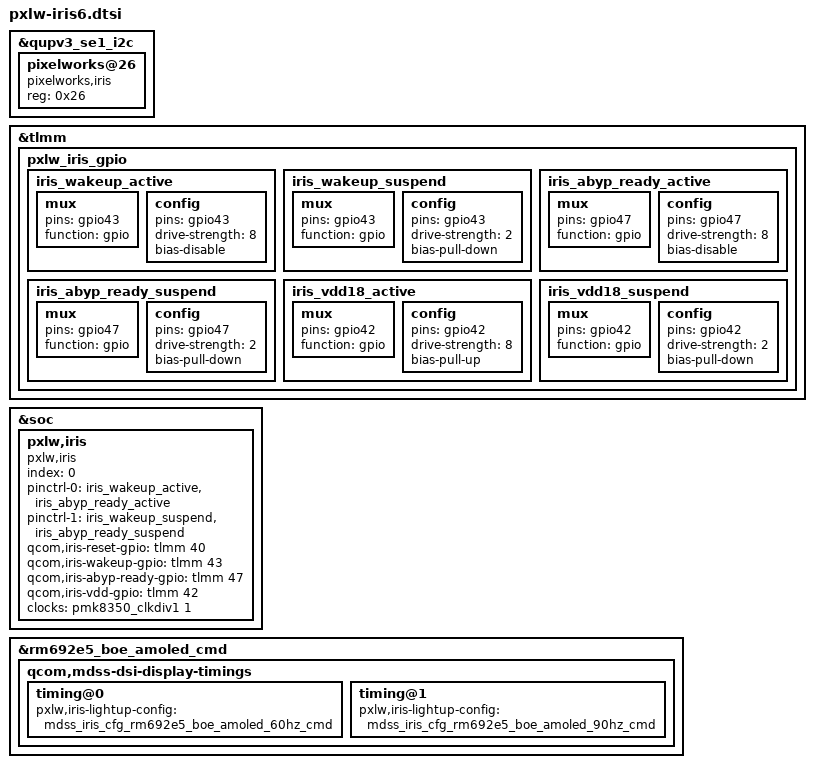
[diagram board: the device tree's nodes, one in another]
/* Copyright (c) 2020, Pixelworks
 *
 * This program is free software; you can redistribute it and/or modify
 * it under the terms of the GNU General Public License version 2 and
 * only version 2 as published by the Free Software Foundation.
 *
 * This program is distributed in the hope that it will be useful,
 * but WITHOUT ANY WARRANTY; without even the implied warranty of
 * MERCHANTABILITY or FITNESS FOR A PARTICULAR PURPOSE.  See the
 * GNU General Public License for more details.
 */

#include "pxlw-iris6-cfg-rm692e5_boe-60hz-fhdplus-dsc-cmd.dtsi"
#include "pxlw-iris6-cfg-rm692e5_boe-90hz-fhdplus-dsc-cmd.dtsi"

&qupv3_se1_i2c {
        status = "ok";
        pixelworks@26 {  //i2c: 22, i3c: 26
                status = "ok";
                compatible = "pixelworks,iris";
                reg = <0x26>;
        };
};

&tlmm {
	pxlw_iris_gpio: pxlw_iris_gpio {
		iris_wakeup_active: iris_wakeup_active {
			mux {
				pins = "gpio43";
				function = "gpio";
			};

			config {
				pins = "gpio43";
				drive-strength = <8>;
				bias-disable;
			};
		};

		iris_wakeup_suspend: iris_wakeup_suspend {
			mux {
				pins = "gpio43";
				function = "gpio";
			};

			config {
				pins = "gpio43";
				drive-strength = <2>;
				bias-pull-down;
			};
		};

		iris_abyp_ready_active: iris_abyp_ready_active {
			mux {
				pins = "gpio47";
				function = "gpio";
			};

			config {
				pins = "gpio47";
				drive-strength = <8>;
				bias-disable;
			};
		};

		iris_abyp_ready_suspend: iris_abyp_ready_suspend {
			mux {
				pins = "gpio47";
				function = "gpio";
			};

			config {
				pins = "gpio47";
				drive-strength = <2>;
				bias-pull-down;
			};
		};
		iris_vdd18_active: iris_vdd18_active {
			mux {
				pins = "gpio42";
				function = "gpio";
			};

			config {
				pins = "gpio42";
				drive-strength = <8>;
				bias-pull-up;
			};
		};

		iris_vdd18_suspend: iris_vdd18_suspend {
			mux {
				pins = "gpio42";
				function = "gpio";
			};

			config {
				pins = "gpio42";
				drive-strength = <2>;
				bias-pull-down;
			};
		};
	};
};

&soc {
	pxlw,iris {
		compatible = "pxlw,iris";
		index = <0>;

		pinctrl-names = "iris_active", "iris_suspend";
		pinctrl-0 = <&iris_wakeup_active &iris_abyp_ready_active>;
		pinctrl-1 = <&iris_wakeup_suspend &iris_abyp_ready_suspend>;

		qcom,iris-reset-gpio = <&tlmm 40 0>;
		qcom,iris-wakeup-gpio = <&tlmm 43 0>;
		qcom,iris-abyp-ready-gpio = <&tlmm 47 0>;
		qcom,iris-vdd-gpio = <&tlmm 42 0>;

		clocks = <&pmk8350_clkdiv1 1>;
		clock-names = "iris_clk";
	};
};

&rm692e5_boe_amoled_cmd {
	qcom,mdss-dsi-display-timings {
		timing@0{
			pxlw,iris-lightup-config = <&mdss_iris_cfg_rm692e5_boe_amoled_60hz_cmd>; 
		};
		timing@1{
			pxlw,iris-lightup-config = <&mdss_iris_cfg_rm692e5_boe_amoled_90hz_cmd>; 
		};		
	};
};
